VERSION ""

NS_ :

BS_:

BU_: New_Node_1

BO_ 1901 Uds_Tx: 8 New_Node_1
 SG_ Can_uds_tx : 7|64@0+ (1,0) [0|0] "" Vector__XXX

BO_ 1893 Uds_Rx_Phy: 8 Vector__XXX
 SG_ Can_uds_rx_phy : 7|64@0+ (1,0) [0|0] ""  New_Node_1

BO_ 2015 Uds_Rx_Fun: 8 Vector__XXX
 SG_ Can_uds_rx_fun : 7|64@0- (1,0) [0|0] ""  New_Node_1

BO_ 1536 Can_Nm: 8 New_Node_1
 SG_ Can_Nm_msg : 7|64@0+ (1,0) [0|0] "" Vector__XXX

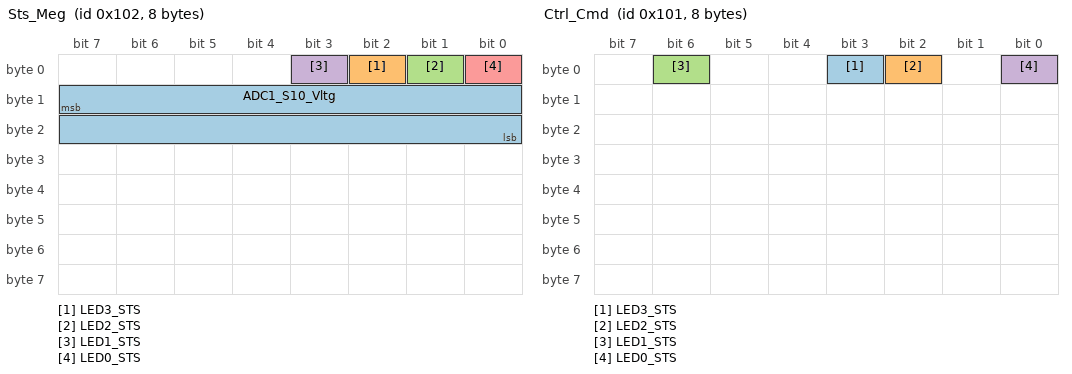
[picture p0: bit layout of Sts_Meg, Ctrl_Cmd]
BO_ 258 Sts_Meg: 8 New_Node_1
 SG_ ADC1_S10_Vltg : 15|16@0+ (0.001,0) [0|0] "" Vector__XXX
 SG_ LED3_STS : 2|1@0+ (1,0) [0|0] "" Vector__XXX
 SG_ LED2_STS : 1|1@0+ (1,0) [0|0] "" Vector__XXX
 SG_ LED1_STS : 3|1@0+ (1,0) [0|0] "" Vector__XXX
 SG_ LED0_STS : 0|1@0+ (1,0) [0|0] "" Vector__XXX

BO_ 257 Ctrl_Cmd: 8 Vector__XXX
 SG_ LED3_STS : 3|1@0+ (1,0) [0|0] ""  New_Node_1
 SG_ LED2_STS : 2|1@0+ (1,0) [0|0] ""  New_Node_1
 SG_ LED1_STS : 6|1@0+ (1,0) [0|0] ""  New_Node_1
 SG_ LED0_STS : 0|1@0+ (1,0) [0|0] ""  New_Node_1

BA_DEF_ BO_  "CANFD_BRS" ENUM  "0","1";
BA_DEF_  "DBName" STRING ;
BA_DEF_  "BusType" STRING ;
BA_DEF_ BO_  "VFrameFormat" ENUM  "StandardCAN","ExtendedCAN","reserved","reserved","reserved","reserved","reserved","reserved","reserved","reserved","reserved","reserved","reserved","reserved","StandardCAN_FD","ExtendedCAN_FD";
BA_DEF_DEF_  "CANFD_BRS" "1";
BA_DEF_DEF_  "DBName" "";
BA_DEF_DEF_  "BusType" "";
BA_DEF_DEF_  "VFrameFormat" "StandardCAN";
BA_ "BusType" "CAN FD";
BA_ "DBName" "S32K344_DEMO";
BA_ "VFrameFormat" BO_ 1901 14;
BA_ "VFrameFormat" BO_ 1893 14;
BA_ "VFrameFormat" BO_ 2015 14;
BA_ "VFrameFormat" BO_ 1536 14;
BA_ "VFrameFormat" BO_ 258 14;
BA_ "VFrameFormat" BO_ 257 14;
